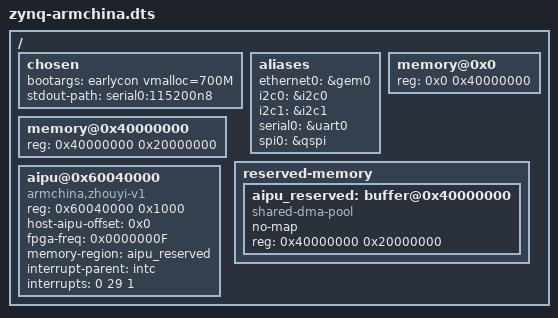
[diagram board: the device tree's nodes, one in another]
/*
 * CAUTION: This file is automatically generated by Xilinx.
 * Version:
 * Today is: Tue Apr 16 23:52:52 2019
 */


/dts-v1/;
/include/ "zynq-7000.dtsi"
///include/ "pl.dtsi"
/include/ "pcw.dtsi"
/ {
	chosen {
		bootargs = "earlycon vmalloc=700M";
		stdout-path = "serial0:115200n8";
	};
	aliases {
		ethernet0 = &gem0;
		i2c0 = &i2c0;
		i2c1 = &i2c1;
		serial0 = &uart0;
		spi0 = &qspi;
	};
        memory@0x0 {
                device_type = "memory";
                reg = <0x0 0x40000000>;
        };
        memory@0x40000000 {
                device_type = "memory";
                reg = <0x40000000 0x20000000>;
        };
        reserved-memory {
                #address-cells = <1>;
		#size-cells = <1>;
		ranges;

                aipu_reserved: buffer@0x40000000 {
                    compatible = "shared-dma-pool";
                    no-map;
                    reg = <0x40000000 0x20000000>;
                };
        };

        aipu@0x60040000 {
               compatible = "armchina,zhouyi-v1";
               reg = <0x60040000 0x1000>;
               host-aipu-offset = <0x0>;
               fpga-freq = <0x0000000F>;
               memory-region = <&aipu_reserved>;
               interrupt-parent = <&intc>;
               interrupts = <0 29 1>; /* irq = 61 - 32 */
        };
};
#include "system-user.dtsi"
